# STM32F765BGT6 register map
File version: 1.0
Registers are 32-bit, access not given, reset 0x0 unless marked. A register's access mark holds for its fields unless they carry their own. Offsets are from the block's base; [hi:lo] are bit positions; {n}, {i} and the like mark numbered series.

## TIM1
Base 0x40010000
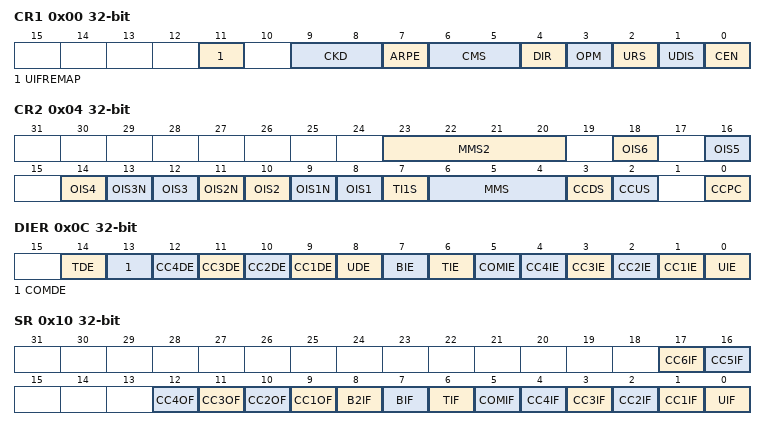
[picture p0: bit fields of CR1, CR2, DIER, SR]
0x00 CR1
  [11] UIFREMAP, [9:8] CKD, [7] ARPE, [6:5] CMS, [4] DIR, [3] OPM, [2] URS, [1] UDIS, [0] CEN
0x04 CR2
  [23:20] MMS2, [2n+6] OIS{n} (n=1..6), [13] OIS3N, [11] OIS2N, [9] OIS1N, [7] TI1S, [6:4] MMS, [3] CCDS, [2] CCUS, [0] CCPC
0x08 SMCR
  [15] ETP, [14] ECE, [13:12] ETPS, [11:8] ETF, [7] MSM, [6:4] TS, [16:0] SMS
0x0C DIER
  [14] TDE, [13] COMDE, [n+8] CC{n}DE (n=1..4), [8] UDE, [7] BIE, [6] TIE, [5] COMIE, [n] CC{n}IE (n=1..4), [0] UIE
0x10 SR
  [17] CC6IF, [16] CC5IF, [n+8] CC{n}OF (n=1..4), [8] B2IF, [7] BIF, [6] TIF, [5] COMIF, [n] CC{n}IF (n=1..4), [0] UIF
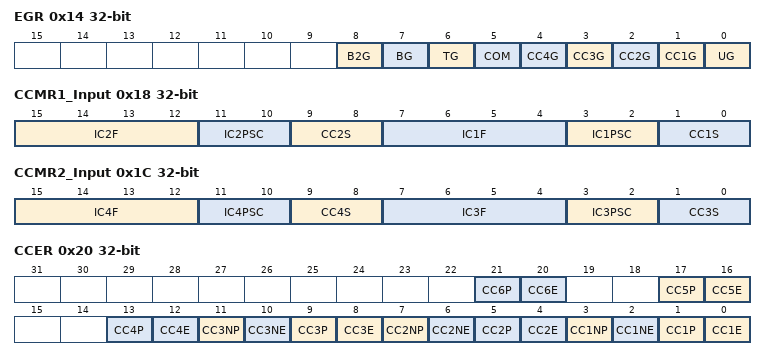
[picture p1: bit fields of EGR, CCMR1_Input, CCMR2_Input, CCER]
0x14 EGR
  [8] B2G, [7] BG, [6] TG, [5] COM, [n] CC{n}G (n=1..4), [0] UG
0x18 CCMR1_Output
  [15] OC2CE, [24:12] OC2M, [11] OC2PE, [10] OC2FE, [9:8] CC2S, [7] OC1CE, [16:4] OC1M, [3] OC1PE, [2] OC1FE, [1:0] CC1S
0x18 CCMR1_Input
  [15:12] IC2F, [11:10] IC2PSC, [9:8] CC2S, [7:4] IC1F, [3:2] IC1PSC, [1:0] CC1S
0x1C CCMR2_Output
  [15] OC4CE, [24:12] OC4M, [11] OC4PE, [10] OC4FE, [9:8] CC4S, [7] OC3CE, [16:4] OC3M, [3] OC3PE, [2] OC3FE, [1:0] CC3S
0x1C CCMR2_Input
  [15:12] IC4F, [11:10] IC4PSC, [9:8] CC4S, [7:4] IC3F, [3:2] IC3PSC, [1:0] CC3S
0x20 CCER
  [4n-3] CC{n}P (n=1..6), [4n-4] CC{n}E (n=1..6), [11] CC3NP, [10] CC3NE, [7] CC2NP, [6] CC2NE, [3] CC1NP, [2] CC1NE
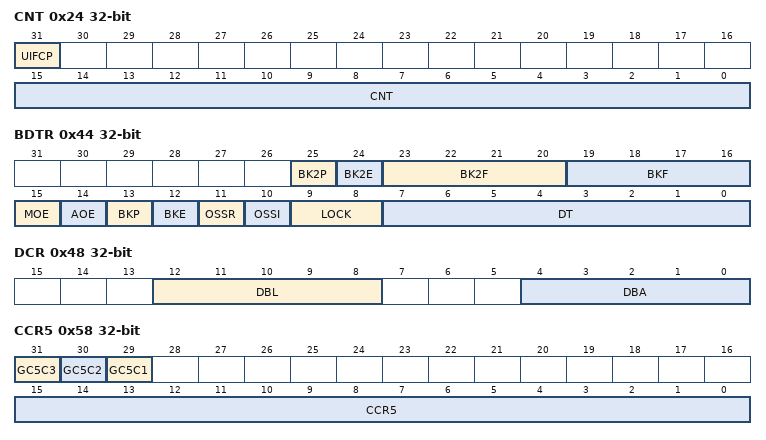
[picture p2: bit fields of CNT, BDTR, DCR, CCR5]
0x24 CNT
  [31] UIFCP, [15:0] CNT
0x28 PSC
  [15:0] PSC
0x2C ARR
  [15:0] ARR
0x30 RCR
  [15:0] REP
{0x30+4i} CCR{i} (i=1..4)
  [15:0] CCR{i}
0x44 BDTR
  [25] BK2P, [24] BK2E, [23:20] BK2F, [19:16] BKF, [15] MOE, [14] AOE, [13] BKP, [12] BKE, [11] OSSR, [10] OSSI, [9:8] LOCK, [7:0] DT
0x48 DCR
  [12:8] DBL, [4:0] DBA
0x4C DMAR
  [15:0] DMAB
0x54 CCMR3_Output
  [15] OC6CE, [24:12] OC6M, [11] OC6PE, [10] OC6FE, [7] OC5CE, [16:4] OC5M, [3] OC5PE, [2] OC5FE
0x58 CCR5
  [31] GC5C3, [30] GC5C2, [29] GC5C1, [15:0] CCR5
0x5C CCR6
  [15:0] CCR6
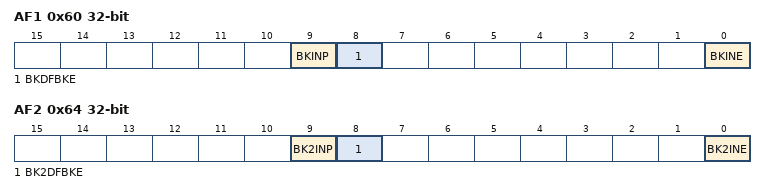
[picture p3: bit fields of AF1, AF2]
0x60 AF1
  [9] BKINP, [8] BKDFBKE, [0] BKINE
0x64 AF2
  [9] BK2INP, [8] BK2DFBKE, [0] BK2INE

## TIM8
Base 0x40010400
Registers as TIM1; these are added or differ:
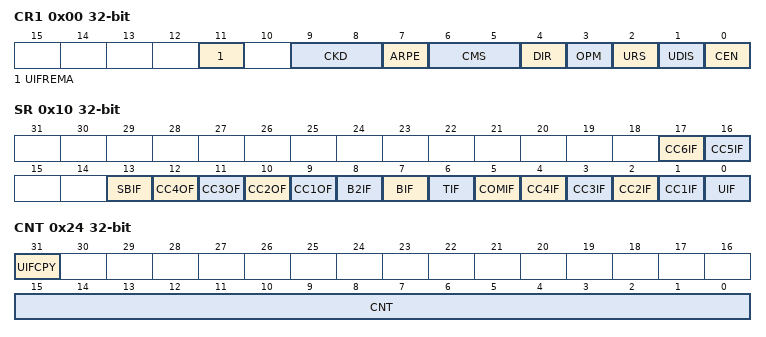
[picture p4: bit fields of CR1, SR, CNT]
0x00 CR1
  [11] UIFREMA, [9:8] CKD, [7] ARPE, [6:5] CMS, [4] DIR, [3] OPM, [2] URS, [1] UDIS, [0] CEN
0x10 SR
  [17] CC6IF, [16] CC5IF, [13] SBIF, [n+8] CC{n}OF (n=1..4), [8] B2IF, [7] BIF, [6] TIF, [5] COMIF, [n] CC{n}IF (n=1..4), [0] UIF
0x24 CNT
  [31] UIFCPY, [15:0] CNT

## SDMMC2
Base 0x40011C00
Same registers: SDMMC1 0x40012C00
0x00 POWER
  [1:0] PWRCTRL
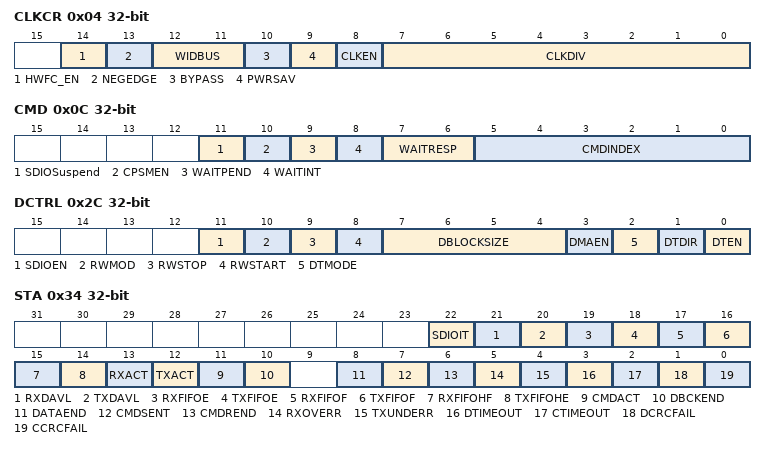
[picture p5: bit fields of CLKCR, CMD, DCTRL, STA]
0x04 CLKCR
  [14] HWFC_EN, [13] NEGEDGE, [12:11] WIDBUS, [10] BYPASS, [9] PWRSAV, [8] CLKEN, [7:0] CLKDIV
0x08 ARG
  [31:0] CMDARG
0x0C CMD
  [11] SDIOSuspend, [10] CPSMEN, [9] WAITPEND, [8] WAITINT, [7:6] WAITRESP, [5:0] CMDINDEX
0x10 RESPCMD
  [5:0] RESPCMD
{0x10+4i} RESP{i} (i=1..4)
  [31:0] CARDSTATUS{i}
0x24 DTIMER
  [31:0] DATATIME
0x28 DLEN
  [24:0] DATALENGTH
0x2C DCTRL
  [11] SDIOEN, [10] RWMOD, [9] RWSTOP, [8] RWSTART, [7:4] DBLOCKSIZE, [3] DMAEN, [2] DTMODE, [1] DTDIR, [0] DTEN
0x30 DCOUNT
  [24:0] DATACOUNT
0x34 STA
  [22] SDIOIT, [21] RXDAVL, [20] TXDAVL, [19] RXFIFOE, [18] TXFIFOE, [17] RXFIFOF, [16] TXFIFOF, [15] RXFIFOHF, [14] TXFIFOHE, [13] RXACT, [12] TXACT, [11] CMDACT, [10] DBCKEND, [8] DATAEND, [7] CMDSENT, [6] CMDREND, [5] RXOVERR, [4] TXUNDERR, [3] DTIMEOUT, [2] CTIMEOUT, [1] DCRCFAIL, [0] CCRCFAIL
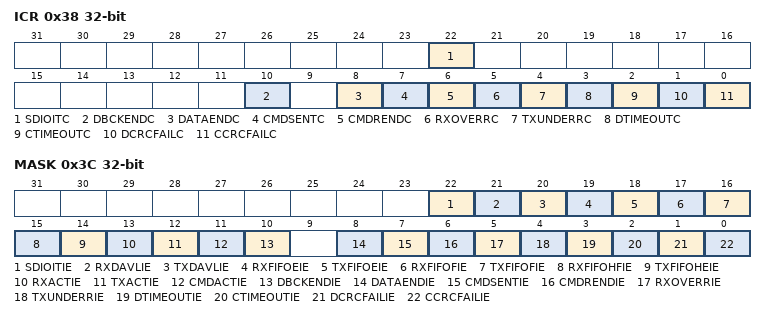
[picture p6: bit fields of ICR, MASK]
0x38 ICR
  [22] SDIOITC, [10] DBCKENDC, [8] DATAENDC, [7] CMDSENTC, [6] CMDRENDC, [5] RXOVERRC, [4] TXUNDERRC, [3] DTIMEOUTC, [2] CTIMEOUTC, [1] DCRCFAILC, [0] CCRCFAILC
0x3C MASK
  [22] SDIOITIE, [21] RXDAVLIE, [20] TXDAVLIE, [19] RXFIFOEIE, [18] TXFIFOEIE, [17] RXFIFOFIE, [16] TXFIFOFIE, [15] RXFIFOHFIE, [14] TXFIFOHEIE, [13] RXACTIE, [12] TXACTIE, [11] CMDACTIE, [10] DBCKENDIE, [8] DATAENDIE, [7] CMDSENTIE, [6] CMDRENDIE, [5] RXOVERRIE, [4] TXUNDERRIE, [3] DTIMEOUTIE, [2] CTIMEOUTIE, [1] DCRCFAILIE, [0] CCRCFAILIE
0x48 FIFOCNT
  [23:0] FIFOCOUNT
0x80 FIFO
  [31:0] FIF0Data
